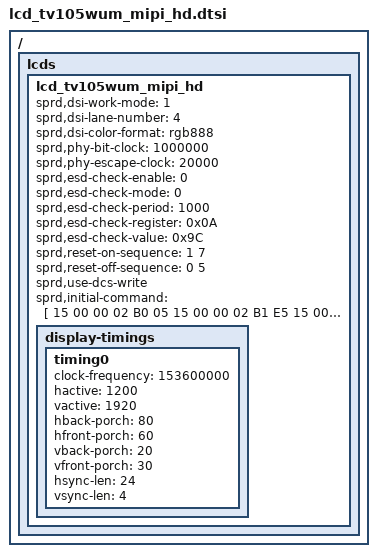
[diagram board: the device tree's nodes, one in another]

/*
 * tv105wum LCD config dtsi file for spreadtrum
 *
 * Copyright (C) 2018, Spreadtrum Communications Inc.
 *
 * SPDX-License-Identifier: (GPL-2.0+ OR MIT)
 */

/ { lcds {
	lcd_tv105wum_mipi_hd: lcd_tv105wum_mipi_hd {

		sprd,dsi-work-mode = <1>; /* video burst mode*/
		sprd,dsi-lane-number = <4>;
		sprd,dsi-color-format = "rgb888";

		sprd,phy-bit-clock = <1000000>;	/* kbps */
		sprd,phy-escape-clock = <20000>;/* kHz */

		/*
		sprd,width-mm = <68>;
		sprd,height-mm = <121>;
		*/

		sprd,esd-check-enable = <0>;
		sprd,esd-check-mode = <0>;
		sprd,esd-check-period = <1000>;
		sprd,esd-check-register = <0x0A>;
		sprd,esd-check-value = <0x9C>;

		sprd,reset-on-sequence = <1 7>;
		sprd,reset-off-sequence = <0 5>;

		sprd,use-dcs-write;
		sprd,initial-command = [
		15 00 00 02 B0 05
		15 00 00 02 B1 E5
		15 00 00 02 B3 52
		15 00 00 02 B0 00
		/*15 00 00 02 B3 88*/
		15 00 00 02 B0 04
		15 00 00 02 B8 00
		15 00 00 02 B0 00
		15 00 00 02 B6 03
		/*15 00 00 02 B2 41*/
		15 00 00 02 BA 87
		15 00 00 02 BF 1F
		15 00 00 02 C0 0F
		15 00 00 02 C2 0C
		15 00 00 02 C3 02
		15 00 00 02 C4 0C
		15 00 00 02 C5 02
		15 00 00 02 B0 01
		15 00 00 02 E0 26
		15 00 00 02 E1 26
		15 00 00 02 DC 00
		15 00 00 02 DD 00
		15 00 00 02 CC 26
		15 00 00 02 CD 26
		15 00 00 02 C8 00
		15 00 00 02 C9 00
		15 00 00 02 D2 03
		15 00 00 02 D3 03
		15 00 00 02 E6 04
		15 00 00 02 E7 04
		15 00 00 02 C4 09
		15 00 00 02 C5 09
		15 00 00 02 D8 0A
		15 00 00 02 D9 0A
		15 00 00 02 C2 0B
		15 00 00 02 C3 0B
		15 00 00 02 D6 0C
		15 00 00 02 D7 0C
		15 00 00 02 C0 05
		15 00 00 02 C1 05
		15 00 00 02 D4 06
		15 00 00 02 D5 06
		15 00 00 02 CA 07
		15 00 00 02 CB 07
		15 00 00 02 DE 08
		15 00 00 02 DF 08
		15 00 00 02 B0 02
		15 00 00 02 C0 00
		15 00 00 02 C1 0F
		15 00 00 02 C2 1A
		15 00 00 02 C3 2B
		15 00 00 02 C4 38
		15 00 00 02 C5 39
		15 00 00 02 C6 38
		15 00 00 02 C7 38
		15 00 00 02 C8 36
		15 00 00 02 C9 34
		15 00 00 02 CA 35
		15 00 00 02 CB 36
		15 00 00 02 CC 39
		15 00 00 02 CD 2D
		15 00 00 02 CE 2E
		15 00 00 02 CF 2F
		15 00 00 02 D0 07
		15 00 00 02 D2 00
		15 00 00 02 D3 0F
		15 00 00 02 D4 1A
		15 00 00 02 D5 2B
		15 00 00 02 D6 3B
		15 00 00 02 D7 39
		15 00 00 02 D8 38
		15 00 00 02 D9 38
		15 00 00 02 DA 36
		15 00 00 02 DB 34
		15 00 00 02 DC 35
		15 00 00 02 DD 36
		15 00 00 02 DE 39
		15 00 00 02 DF 2D
		15 00 00 02 E0 2E
		15 00 00 02 E1 2F
		15 00 00 02 E2 07
		15 00 00 02 B0 03
		15 00 00 02 C8 0B
		15 00 00 02 C9 07
		15 00 00 02 C3 00
		15 00 00 02 E7 00
		15 00 00 02 C5 2A
		15 00 00 02 DE 2A
		15 00 00 02 CA 43
		15 00 00 02 C9 07
		15 00 00 02 E4 C0
		15 00 00 02 E5 0D
		15 00 00 02 CB 00
		15 00 00 02 B0 06
		15 00 00 02 B8 A5
		15 00 00 02 C0 A5
		15 00 00 02 C7 0F
		15 00 00 02 D5 32
		15 00 00 02 BC 33
		15 00 00 02 B0 07
		15 00 00 02 B1 00
		15 00 00 02 B2 16
		15 00 00 02 B3 24
		15 00 00 02 B4 3B
		15 00 00 02 B5 51
		15 00 00 02 B6 63
		15 00 00 02 B7 87
		15 00 00 02 B8 AC
		15 00 00 02 B9 F5
		15 00 00 02 BA 39
		15 00 00 02 BB BB
		15 00 00 02 BC 3F
		15 00 00 02 BD 43
		15 00 00 02 BE BE
		15 00 00 02 BF 32
		15 00 00 02 C0 69
		15 00 00 02 C1 9F
		15 00 00 02 C2 BA
		15 00 00 02 C3 D3
		15 00 00 02 C4 DE
		15 00 00 02 C5 E9
		15 00 00 02 C6 F5
		15 00 00 02 C7 FA
		15 00 00 02 C8 FC
		15 00 00 02 C9 00
		15 00 00 02 CA 00
		15 00 00 02 CB 16
		15 00 00 02 CC AF
		15 00 00 02 CD FF
		15 00 00 02 CE FF
		15 00 00 02 B0 08
		15 00 00 02 B1 00
		15 00 00 02 B2 16
		15 00 00 02 B3 24
		15 00 00 02 B4 3B
		15 00 00 02 B5 51
		15 00 00 02 B6 63
		15 00 00 02 B7 87
		15 00 00 02 B8 AC
		15 00 00 02 B9 F5
		15 00 00 02 BA 39
		15 00 00 02 BB BB
		15 00 00 02 BC 3F
		15 00 00 02 BD 43
		15 00 00 02 BE BE
		15 00 00 02 BF 32
		15 00 00 02 C0 69
		15 00 00 02 C1 9F
		15 00 00 02 C2 BA
		15 00 00 02 C3 D3
		15 00 00 02 C4 DE
		15 00 00 02 C5 E9
		15 00 00 02 C6 F5
		15 00 00 02 C7 FA
		15 00 00 02 C8 FC
		15 00 00 02 C9 00
		15 00 00 02 CA 00
		15 00 00 02 CB 16
		15 00 00 02 CC AF
		15 00 00 02 CD FF
		15 00 00 02 CE FF
		15 00 00 02 B0 09
		15 00 00 02 B1 00
		15 00 00 02 B2 16
		15 00 00 02 B3 24
		15 00 00 02 B4 3B
		15 00 00 02 B5 51
		15 00 00 02 B6 63
		15 00 00 02 B7 87
		15 00 00 02 B8 AC
		15 00 00 02 B9 F5
		15 00 00 02 BA 39
		15 00 00 02 BB BB
		15 00 00 02 BC 3F
		15 00 00 02 BD 43
		15 00 00 02 BE BE
		15 00 00 02 BF 32
		15 00 00 02 C0 69
		15 00 00 02 C1 9F
		15 00 00 02 C2 BA
		15 00 00 02 C3 D3
		15 00 00 02 C4 DE
		15 00 00 02 C5 E9
		15 00 00 02 C6 F5
		15 00 00 02 C7 FA
		15 00 00 02 C8 FC
		15 00 00 02 C9 00
		15 00 00 02 CA 00
		15 00 00 02 CB 16
		15 00 00 02 CC AF
		15 00 00 02 CD FF
		15 00 00 02 CE FF
		15 00 00 02 B0 0A
		15 00 00 02 B1 00
		15 00 00 02 B2 16
		15 00 00 02 B3 24
		15 00 00 02 B4 3B
		15 00 00 02 B5 51
		15 00 00 02 B6 63
		15 00 00 02 B7 87
		15 00 00 02 B8 AC
		15 00 00 02 B9 F5
		15 00 00 02 BA 39
		15 00 00 02 BB BB
		15 00 00 02 BC 3F
		15 00 00 02 BD 43
		15 00 00 02 BE BE
		15 00 00 02 BF 32
		15 00 00 02 C0 69
		15 00 00 02 C1 9F
		15 00 00 02 C2 BA
		15 00 00 02 C3 D3
		15 00 00 02 C4 DE
		15 00 00 02 C5 E9
		15 00 00 02 C6 F5
		15 00 00 02 C7 FA
		15 00 00 02 C8 FC
		15 00 00 02 C9 00
		15 00 00 02 CA 00
		15 00 00 02 CB 16
		15 00 00 02 CC AF
		15 00 00 02 CD FF
		15 00 00 02 CE FF
		15 00 00 02 B0 0B
		15 00 00 02 B1 00
		15 00 00 02 B2 16
		15 00 00 02 B3 24
		15 00 00 02 B4 3B
		15 00 00 02 B5 51
		15 00 00 02 B6 63
		15 00 00 02 B7 87
		15 00 00 02 B8 AC
		15 00 00 02 B9 F5
		15 00 00 02 BA 39
		15 00 00 02 BB BB
		15 00 00 02 BC 3F
		15 00 00 02 BD 43
		15 00 00 02 BE BE
		15 00 00 02 BF 32
		15 00 00 02 C0 69
		15 00 00 02 C1 9F
		15 00 00 02 C2 BA
		15 00 00 02 C3 D3
		15 00 00 02 C4 DE
		15 00 00 02 C5 E9
		15 00 00 02 C6 F5
		15 00 00 02 C7 FA
		15 00 00 02 C8 FC
		15 00 00 02 C9 00
		15 00 00 02 CA 00
		15 00 00 02 CB 16
		15 00 00 02 CC AF
		15 00 00 02 CD FF
		15 00 00 02 CE FF
		15 00 00 02 B0 0C
		15 00 00 02 B1 00
		15 00 00 02 B2 16
		15 00 00 02 B3 24
		15 00 00 02 B4 3B
		15 00 00 02 B5 51
		15 00 00 02 B6 63
		15 00 00 02 B7 87
		15 00 00 02 B8 AC
		15 00 00 02 B9 F5
		15 00 00 02 BA 39
		15 00 00 02 BB BB
		15 00 00 02 BC 3F
		15 00 00 02 BD 43
		15 00 00 02 BE BE
		15 00 00 02 BF 32
		15 00 00 02 C0 69
		15 00 00 02 C1 9F
		15 00 00 02 C2 BA
		15 00 00 02 C3 D3
		15 00 00 02 C4 DE
		15 00 00 02 C5 E9
		15 00 00 02 C6 F5
		15 00 00 02 C7 FA
		15 00 00 02 C8 FC
		15 00 00 02 C9 00
		15 00 00 02 CA 00
		15 00 00 02 CB 16
		15 00 00 02 CC AF
		15 00 00 02 CD FF
		15 64 00 02 CE FF
		15 00 00 02 B0 00
		15 00 00 02 B3 08
		15 00 00 02 B0 04
		15 0A 00 02 B8 68
		05 64 00 01 11
		05 32 00 01 29
			];

		/*
		sprd,sleep-in-command = [
			15 32 00 01 28
			15 96 00 01 10
			29 00 00 02 B0 00
			29 14 00 02 B1 01
			];

		sprd,sleep-out-command = [
			15 78 00 01 11
			15 32 00 01 29
			15 01 00 02 B0 00
			15 01 00 02 B1 01
			];
		*/

		display-timings {
			timing0 {
				clock-frequency = <153600000>;
				hactive = <1200>;
				vactive = <1920>;
				hback-porch = <80>;
				hfront-porch = <60>;
				vback-porch = <20>;
				vfront-porch = <30>;
				hsync-len = <24>;
				vsync-len = <4>;
			};
		};
	};
};};
